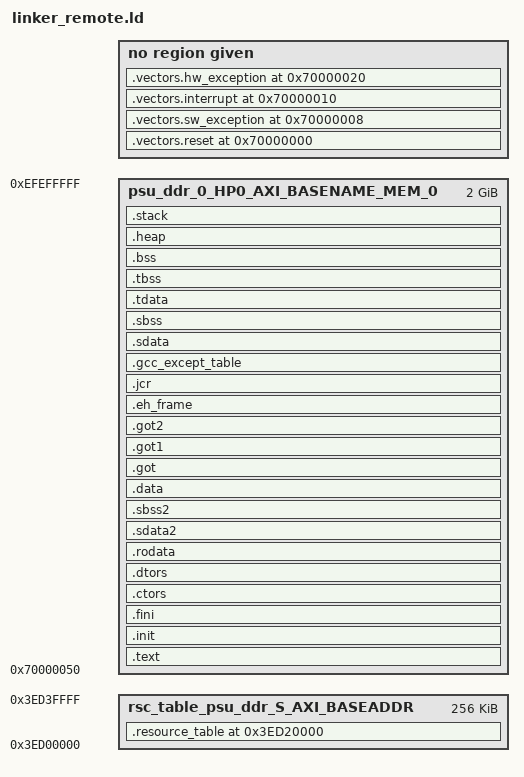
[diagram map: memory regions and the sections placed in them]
/*******************************************************************/
/*                                                                 */
/* This file is automatically generated by linker script generator.*/
/*                                                                 */
/* Version: 2020.1.0                                               */
/*                                                                 */
/* Copyright (c) 2010-2020 Xilinx, Inc.  All rights reserved.      */
/*                                                                 */
/* Description : MicroBlaze Linker Script                           */
/*                                                                 */
/*******************************************************************/

_STACK_SIZE = DEFINED(_STACK_SIZE) ? _STACK_SIZE : 0x400;
_HEAP_SIZE = DEFINED(_HEAP_SIZE) ? _HEAP_SIZE :   0x1800;

/* Define Memories in the system */

MEMORY
{
   psu_ddr_0_HP0_AXI_BASENAME_MEM_0 : ORIGIN = 0x70000050, LENGTH = 0x7FEFFFB0
   rsc_table_psu_ddr_S_AXI_BASEADDR : ORIGIN = 0x3ED00000, LENGTH = 0x00040000
}

/* Specify the default entry point to the program */

ENTRY(_start)

/* Define the sections, and where they are mapped in memory */

SECTIONS
{
.vectors.reset 0x70000000 : {
   KEEP (*(.vectors.reset))
}

.vectors.sw_exception 0x70000008 : {
   KEEP (*(.vectors.sw_exception))
}

.vectors.interrupt 0x70000010 : {
   KEEP (*(.vectors.interrupt))
}

.vectors.hw_exception 0x70000020 : {
   KEEP (*(.vectors.hw_exception))
}

.text : {
   *(.text)
   *(.text.*)
   *(.gnu.linkonce.t.*)
} > psu_ddr_0_HP0_AXI_BASENAME_MEM_0

.init : {
   KEEP (*(.init))
} > psu_ddr_0_HP0_AXI_BASENAME_MEM_0

.fini : {
   KEEP (*(.fini))
} > psu_ddr_0_HP0_AXI_BASENAME_MEM_0

.ctors : {
   __CTOR_LIST__ = .;
   ___CTORS_LIST___ = .;
   KEEP (*crtbegin.o(.ctors))
   KEEP (*(EXCLUDE_FILE(*crtend.o) .ctors))
   KEEP (*(SORT(.ctors.*)))
   KEEP (*(.ctors))
   __CTOR_END__ = .;
   ___CTORS_END___ = .;
} > psu_ddr_0_HP0_AXI_BASENAME_MEM_0

.dtors : {
   __DTOR_LIST__ = .;
   ___DTORS_LIST___ = .;
   KEEP (*crtbegin.o(.dtors))
   KEEP (*(EXCLUDE_FILE(*crtend.o) .dtors))
   KEEP (*(SORT(.dtors.*)))
   KEEP (*(.dtors))
   PROVIDE(__DTOR_END__ = .);
   PROVIDE(___DTORS_END___ = .);
} > psu_ddr_0_HP0_AXI_BASENAME_MEM_0

.rodata : {
   __rodata_start = .;
   *(.rodata)
   *(.rodata.*)
   *(.gnu.linkonce.r.*)
   __rodata_end = .;
} > psu_ddr_0_HP0_AXI_BASENAME_MEM_0

.sdata2 : {
   . = ALIGN(8);
   __sdata2_start = .;
   *(.sdata2)
   *(.sdata2.*)
   *(.gnu.linkonce.s2.*)
   . = ALIGN(8);
   __sdata2_end = .;
} > psu_ddr_0_HP0_AXI_BASENAME_MEM_0

.sbss2 : {
   __sbss2_start = .;
   *(.sbss2)
   *(.sbss2.*)
   *(.gnu.linkonce.sb2.*)
   __sbss2_end = .;
} > psu_ddr_0_HP0_AXI_BASENAME_MEM_0

.data : {
   . = ALIGN(4);
   __data_start = .;
   *(.data)
   *(.data.*)
   *(.gnu.linkonce.d.*)
   __data_end = .;
} > psu_ddr_0_HP0_AXI_BASENAME_MEM_0

.got : {
   *(.got)
} > psu_ddr_0_HP0_AXI_BASENAME_MEM_0

.got1 : {
   *(.got1)
} > psu_ddr_0_HP0_AXI_BASENAME_MEM_0

.got2 : {
   *(.got2)
} > psu_ddr_0_HP0_AXI_BASENAME_MEM_0

.eh_frame : {
   *(.eh_frame)
} > psu_ddr_0_HP0_AXI_BASENAME_MEM_0

.jcr : {
   *(.jcr)
} > psu_ddr_0_HP0_AXI_BASENAME_MEM_0

.gcc_except_table : {
   *(.gcc_except_table)
} > psu_ddr_0_HP0_AXI_BASENAME_MEM_0

.sdata : {
   . = ALIGN(8);
   __sdata_start = .;
   *(.sdata)
   *(.sdata.*)
   *(.gnu.linkonce.s.*)
   __sdata_end = .;
} > psu_ddr_0_HP0_AXI_BASENAME_MEM_0

.sbss (NOLOAD) : {
   . = ALIGN(4);
   __sbss_start = .;
   *(.sbss)
   *(.sbss.*)
   *(.gnu.linkonce.sb.*)
   . = ALIGN(8);
   __sbss_end = .;
} > psu_ddr_0_HP0_AXI_BASENAME_MEM_0

.tdata : {
   __tdata_start = .;
   *(.tdata)
   *(.tdata.*)
   *(.gnu.linkonce.td.*)
   __tdata_end = .;
} > psu_ddr_0_HP0_AXI_BASENAME_MEM_0

.tbss : {
   __tbss_start = .;
   *(.tbss)
   *(.tbss.*)
   *(.gnu.linkonce.tb.*)
   __tbss_end = .;
} > psu_ddr_0_HP0_AXI_BASENAME_MEM_0

.bss (NOLOAD) : {
   . = ALIGN(4);
   __bss_start = .;
   *(.bss)
   *(.bss.*)
   *(.gnu.linkonce.b.*)
   *(COMMON)
   . = ALIGN(4);
   __bss_end = .;
} > psu_ddr_0_HP0_AXI_BASENAME_MEM_0

_SDA_BASE_ = __sdata_start + ((__sbss_end - __sdata_start) / 2 );

_SDA2_BASE_ = __sdata2_start + ((__sbss2_end - __sdata2_start) / 2 );

/* Generate Stack and Heap definitions */

.heap (NOLOAD) : {
   . = ALIGN(8);
   _heap = .;
   _heap_start = .;
   . += _HEAP_SIZE;
   _heap_end = .;
} > psu_ddr_0_HP0_AXI_BASENAME_MEM_0

.stack (NOLOAD) : {
   _stack_end = .;
   . += _STACK_SIZE;
   . = ALIGN(8);
   _stack = .;
   __stack = _stack;
} > psu_ddr_0_HP0_AXI_BASENAME_MEM_0

/* Linux must have reserved-memory node for this resource_table */
.resource_table 0x3ed20000 : {
	. = ALIGN(4);
	*(.resource_table)
} > rsc_table_psu_ddr_S_AXI_BASEADDR

_end = .;
}
